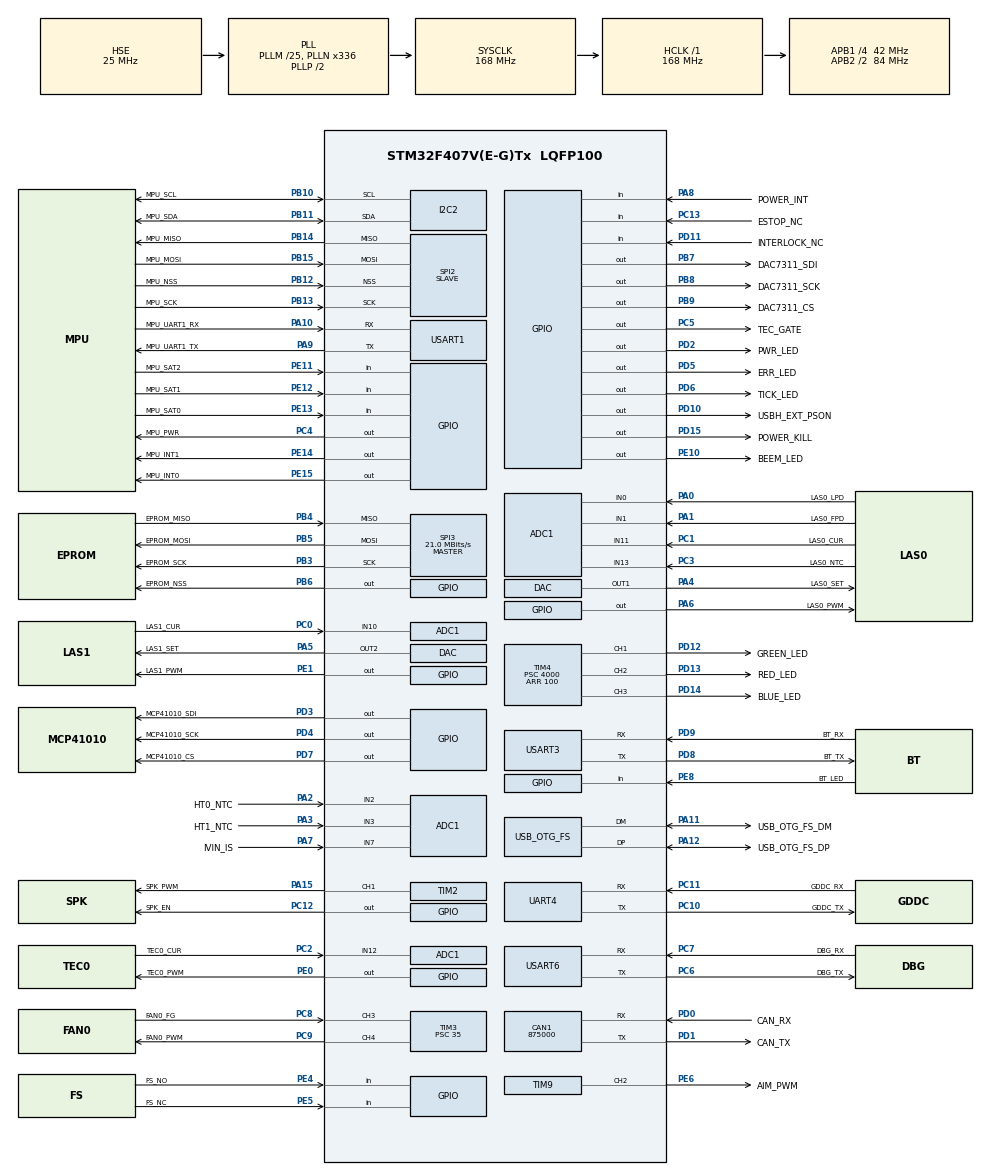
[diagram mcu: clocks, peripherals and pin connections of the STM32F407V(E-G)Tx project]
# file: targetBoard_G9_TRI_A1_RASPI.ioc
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ADC1.Channel-0\#ChannelRegularConversion=ADC_CHANNEL_0
ADC1.Channel-1\#ChannelRegularConversion=ADC_CHANNEL_1
ADC1.Channel-10\#ChannelRegularConversion=ADC_CHANNEL_VREFINT
ADC1.Channel-11\#ChannelRegularConversion=ADC_CHANNEL_VBAT
ADC1.Channel-2\#ChannelRegularConversion=ADC_CHANNEL_2
ADC1.Channel-3\#ChannelRegularConversion=ADC_CHANNEL_3
ADC1.Channel-4\#ChannelRegularConversion=ADC_CHANNEL_7
ADC1.Channel-5\#ChannelRegularConversion=ADC_CHANNEL_10
ADC1.Channel-6\#ChannelRegularConversion=ADC_CHANNEL_11
ADC1.Channel-7\#ChannelRegularConversion=ADC_CHANNEL_12
ADC1.Channel-8\#ChannelRegularConversion=ADC_CHANNEL_13
ADC1.Channel-9\#ChannelRegularConversion=ADC_CHANNEL_TEMPSENSOR
ADC1.ContinuousConvMode=ENABLE
ADC1.DMAContinuousRequests=ENABLE
ADC1.NbrOfConversion=12
ADC1.NbrOfConversionFlag=1
ADC1.Rank-0\#ChannelRegularConversion=1
ADC1.Rank-1\#ChannelRegularConversion=2
ADC1.Rank-10\#ChannelRegularConversion=11
ADC1.Rank-11\#ChannelRegularConversion=12
ADC1.Rank-2\#ChannelRegularConversion=3
ADC1.Rank-3\#ChannelRegularConversion=4
ADC1.Rank-4\#ChannelRegularConversion=5
ADC1.Rank-5\#ChannelRegularConversion=6
ADC1.Rank-6\#ChannelRegularConversion=7
ADC1.Rank-7\#ChannelRegularConversion=8
ADC1.Rank-8\#ChannelRegularConversion=9
ADC1.Rank-9\#ChannelRegularConversion=10
ADC1.SamplingTime-0\#ChannelRegularConversion=ADC_SAMPLETIME_144CYCLES
ADC1.SamplingTime-1\#ChannelRegularConversion=ADC_SAMPLETIME_144CYCLES
ADC1.SamplingTime-10\#ChannelRegularConversion=ADC_SAMPLETIME_144CYCLES
ADC1.SamplingTime-11\#ChannelRegularConversion=ADC_SAMPLETIME_144CYCLES
ADC1.SamplingTime-2\#ChannelRegularConversion=ADC_SAMPLETIME_144CYCLES
ADC1.SamplingTime-3\#ChannelRegularConversion=ADC_SAMPLETIME_144CYCLES
ADC1.SamplingTime-4\#ChannelRegularConversion=ADC_SAMPLETIME_144CYCLES
ADC1.SamplingTime-5\#ChannelRegularConversion=ADC_SAMPLETIME_144CYCLES
ADC1.SamplingTime-6\#ChannelRegularConversion=ADC_SAMPLETIME_144CYCLES
ADC1.SamplingTime-7\#ChannelRegularConversion=ADC_SAMPLETIME_144CYCLES
ADC1.SamplingTime-8\#ChannelRegularConversion=ADC_SAMPLETIME_144CYCLES
ADC1.SamplingTime-9\#ChannelRegularConversion=ADC_SAMPLETIME_144CYCLES
ADC1.ScanConvMode=ENABLE
ADC1.master=1
CAN1.BS1=CAN_BS1_1TQ
CAN1.BS2=CAN_BS2_1TQ
CAN1.CalculateBaudRate=875000
CAN1.CalculateTimeBit=1142
CAN1.CalculateTimeQuantum=380.95238095238096
DAC.DAC_Trigger=DAC_TRIGGER_NONE
Dma.ADC1.0.Direction=DMA_PERIPH_TO_MEMORY
Dma.ADC1.0.FIFOMode=DMA_FIFOMODE_DISABLE
Dma.ADC1.0.Instance=DMA2_Stream0
Dma.ADC1.0.MemDataAlignment=DMA_MDATAALIGN_HALFWORD
Dma.ADC1.0.MemInc=DMA_MINC_ENABLE
Dma.ADC1.0.Mode=DMA_NORMAL
Dma.ADC1.0.PeriphDataAlignment=DMA_PDATAALIGN_HALFWORD
Dma.ADC1.0.PeriphInc=DMA_PINC_DISABLE
Dma.ADC1.0.Priority=DMA_PRIORITY_LOW
Dma.Request0=ADC1
FATFS._CODE_PAGE=437
FATFS._FS_EXFAT=1
FATFS._FS_LOCK=255
FATFS._STRF_ENCODE=0
FATFS._USE_CHMOD=1
FATFS._USE_EXPAND=1
FATFS._USE_FIND=1
FATFS._USE_FORWARD=1
FATFS._USE_LABEL=1
FATFS._USE_LFN=3
FATFS._USE_MUTEX=1
FREERTOS.Tasks01=defaultTask,24,512,StartDefaultTask,Default,NULL,Dynamic,NULL,NULL;mainAppTask,24,10240,StartMainAppTask,As external,NULL,Dynamic,NULL,NULL
FREERTOS.configENABLE_FPU=1
FREERTOS.configMINIMAL_STACK_SIZE=512
FREERTOS.configTOTAL_HEAP_SIZE=49152
FREERTOS.configUSE_APPLICATION_TASK_TAG=1
I2C2.I2C_Mode=I2C_Fast
Mcu.Family=STM32F4
Mcu.Name=STM32F407V(E-G)Tx
Mcu.Package=LQFP100
NVIC.DMA2_Stream0_IRQn=true\:5\:0\:false\:false\:true\:true\:false\:true\:true
NVIC.OTG_FS_IRQn=true\:5\:0\:false\:false\:true\:true\:false\:true\:true
NVIC.PriorityGroup=NVIC_PRIORITYGROUP_4
NVIC.TIM7_IRQn=true\:5\:0\:false\:false\:true\:true\:true\:true\:true
NVIC.TIM8_TRG_COM_TIM14_IRQn=true\:5\:0\:false\:false\:true\:true\:true\:true\:true
NVIC.TIM8_UP_TIM13_IRQn=true\:15\:0\:false\:false\:true\:false\:false\:true\:true
NVIC.TimeBase=TIM8_UP_TIM13_IRQn
NVIC.TimeBaseIP=TIM13
NVIC.UART4_IRQn=true\:5\:0\:false\:false\:true\:true\:true\:true\:true
PA0-WKUP.GPIO_Label=LAS0_LPD
PA0-WKUP.Signal=ADCx_IN0
PA1.GPIO_Label=LAS0_FPD
PA1.Signal=ADCx_IN1
PA10.GPIO_Label=MPU_UART1_RX
PA10.GPIO_PuPd=GPIO_PULLDOWN
PA10.GPIO_Speed=GPIO_SPEED_FREQ_MEDIUM
PA10.Mode=Asynchronous
PA10.Signal=USART1_RX
PA11.GPIO_Label=USB_OTG_FS_DM
PA11.Mode=Host_Only
PA11.Signal=USB_OTG_FS_DM
PA12.GPIO_Label=USB_OTG_FS_DP
PA12.Mode=Host_Only
PA12.Signal=USB_OTG_FS_DP
PA13.Mode=Serial_Wire
PA13.Signal=SYS_JTMS-SWDIO
PA14.Mode=Serial_Wire
PA14.Signal=SYS_JTCK-SWCLK
PA15.GPIO_Label=SPK_PWM
PA15.GPIO_PuPd=GPIO_PULLDOWN
PA15.Signal=S_TIM2_CH1_ETR
PA2.GPIO_Label=HT0_NTC
PA2.Signal=ADCx_IN2
PA3.GPIO_Label=HT1_NTC
PA3.Signal=ADCx_IN3
PA4.GPIO_Label=LAS0_SET
PA4.Signal=COMP_DAC1_group
PA5.GPIO_Label=LAS1_SET
PA5.Signal=COMP_DAC2_group
PA6.GPIO_Label=LAS0_PWM
PA6.GPIO_PuPd=GPIO_PULLDOWN
PA6.Signal=GPIO_Output
PA7.GPIO_Label=IVIN_IS
PA7.Signal=ADCx_IN7
PA8.GPIO_Label=POWER_INT
PA8.Signal=GPIO_Input
PA9.GPIO_Label=MPU_UART1_TX
PA9.GPIO_PuPd=GPIO_PULLDOWN
PA9.GPIO_Speed=GPIO_SPEED_FREQ_MEDIUM
PA9.Mode=Asynchronous
PA9.Signal=USART1_TX
PB10.GPIO_Label=MPU_SCL
PB10.Mode=I2C
PB10.Signal=I2C2_SCL
PB11.GPIO_Label=MPU_SDA
PB11.Mode=I2C
PB11.Signal=I2C2_SDA
PB12.GPIO_Label=MPU_NSS
PB12.GPIO_PuPd=GPIO_PULLUP
PB12.Mode=NSS_Signal_Hard_Input
PB12.Signal=SPI2_NSS
PB13.GPIO_Label=MPU_SCK
PB13.GPIO_PuPd=GPIO_NOPULL
PB13.Mode=Full_Duplex_Slave
PB13.Signal=SPI2_SCK
PB14.GPIO_Label=MPU_MISO
PB14.GPIO_PuPd=GPIO_NOPULL
PB14.Mode=Full_Duplex_Slave
PB14.Signal=SPI2_MISO
PB15.GPIO_Label=MPU_MOSI
PB15.GPIO_PuPd=GPIO_NOPULL
PB15.Mode=Full_Duplex_Slave
PB15.Signal=SPI2_MOSI
PB3.GPIO_Label=EPROM_SCK
PB3.GPIO_PuPd=GPIO_NOPULL
PB3.Mode=Full_Duplex_Master
PB3.Signal=SPI3_SCK
PB4.GPIO_Label=EPROM_MISO
PB4.GPIO_PuPd=GPIO_NOPULL
PB4.Mode=Full_Duplex_Master
PB4.Signal=SPI3_MISO
PB5.GPIO_Label=EPROM_MOSI
PB5.GPIO_PuPd=GPIO_NOPULL
PB5.Mode=Full_Duplex_Master
PB5.Signal=SPI3_MOSI
PB6.GPIO_Label=EPROM_NSS
PB6.GPIO_PuPd=GPIO_PULLUP
PB6.GPIO_Speed=GPIO_SPEED_FREQ_VERY_HIGH
PB6.PinState=GPIO_PIN_SET
PB6.Signal=GPIO_Output
PB7.GPIO_Label=DAC7311_SDI
PB7.GPIO_PuPd=GPIO_PULLDOWN
PB7.GPIO_Speed=GPIO_SPEED_FREQ_VERY_HIGH
PB7.Signal=GPIO_Output
PB8.GPIO_Label=DAC7311_SCK
PB8.GPIO_PuPd=GPIO_PULLDOWN
PB8.GPIO_Speed=GPIO_SPEED_FREQ_VERY_HIGH
PB8.Signal=GPIO_Output
PB9.GPIO_Label=DAC7311_CS
PB9.GPIO_PuPd=GPIO_PULLUP
PB9.GPIO_Speed=GPIO_SPEED_FREQ_VERY_HIGH
PB9.Signal=GPIO_Output
PC0.GPIO_Label=LAS1_CUR
PC0.Signal=ADCx_IN10
PC1.GPIO_Label=LAS0_CUR
PC1.Signal=ADCx_IN11
PC10.GPIO_Label=GDDC_TX
PC10.GPIO_PuPd=GPIO_PULLDOWN
PC10.GPIO_Speed=GPIO_SPEED_FREQ_MEDIUM
PC10.Mode=Asynchronous
PC10.Signal=UART4_TX
PC11.GPIO_Label=GDDC_RX
PC11.GPIO_PuPd=GPIO_PULLDOWN
PC11.GPIO_Speed=GPIO_SPEED_FREQ_MEDIUM
PC11.Mode=Asynchronous
PC11.Signal=UART4_RX
PC12.GPIO_Label=SPK_EN
PC12.GPIO_PuPd=GPIO_PULLUP
PC12.Signal=GPIO_Output
PC13-ANTI_TAMP.GPIO_Label=ESTOP_NC
PC13-ANTI_TAMP.GPIO_PuPd=GPIO_PULLUP
PC13-ANTI_TAMP.Signal=GPIO_Input
PC2.GPIO_Label=TEC0_CUR
PC2.Signal=ADCx_IN12
PC3.GPIO_Label=LAS0_NTC
PC3.Signal=ADCx_IN13
PC4.GPIO_Label=MPU_PWR
PC4.GPIO_PuPd=GPIO_PULLUP
PC4.Signal=GPIO_Output
PC5.GPIO_Label=TEC_GATE
PC5.GPIO_PuPd=GPIO_PULLDOWN
PC5.Signal=GPIO_Output
PC6.GPIO_Label=DBG_TX
PC6.GPIO_PuPd=GPIO_PULLDOWN
PC6.GPIO_Speed=GPIO_SPEED_FREQ_MEDIUM
PC6.Mode=Asynchronous
PC6.Signal=USART6_TX
PC7.GPIO_Label=DBG_RX
PC7.GPIO_PuPd=GPIO_PULLDOWN
PC7.GPIO_Speed=GPIO_SPEED_FREQ_MEDIUM
PC7.Mode=Asynchronous
PC7.Signal=USART6_RX
PC8.GPIO_Label=FAN0_FG
PC8.GPIO_PuPd=GPIO_PULLUP
PC8.Signal=S_TIM3_CH3
PC9.GPIO_Label=FAN0_PWM
PC9.GPIO_PuPd=GPIO_PULLUP
PC9.Signal=S_TIM3_CH4
PD0.GPIO_Label=CAN_RX
PD0.Mode=CAN_Activate
PD0.Signal=CAN1_RX
PD1.GPIO_Label=CAN_TX
PD1.Mode=CAN_Activate
PD1.Signal=CAN1_TX
PD10.GPIO_Label=USBH_EXT_PSON
PD10.GPIO_PuPd=GPIO_PULLDOWN
PD10.Signal=GPIO_Output
PD11.GPIO_Label=INTERLOCK_NC
PD11.GPIO_PuPd=GPIO_PULLUP
PD11.Signal=GPIO_Input
PD12.GPIO_Label=GREEN_LED
PD12.GPIO_PuPd=GPIO_PULLDOWN
PD12.Signal=S_TIM4_CH1
PD13.GPIO_Label=RED_LED
PD13.GPIO_PuPd=GPIO_PULLDOWN
PD13.Signal=S_TIM4_CH2
PD14.GPIO_Label=BLUE_LED
PD14.GPIO_PuPd=GPIO_PULLDOWN
PD14.Signal=S_TIM4_CH3
PD15.GPIO_Label=POWER_KILL
PD15.GPIO_PuPd=GPIO_PULLDOWN
PD15.Signal=GPIO_Output
PD2.GPIO_Label=PWR_LED
PD2.GPIO_PuPd=GPIO_PULLUP
PD2.Signal=GPIO_Output
PD3.GPIO_Label=MCP41010_SDI
PD3.GPIO_PuPd=GPIO_PULLDOWN
PD3.GPIO_Speed=GPIO_SPEED_FREQ_VERY_HIGH
PD3.Signal=GPIO_Output
PD4.GPIO_Label=MCP41010_SCK
PD4.GPIO_PuPd=GPIO_PULLDOWN
PD4.GPIO_Speed=GPIO_SPEED_FREQ_VERY_HIGH
PD4.Signal=GPIO_Output
PD5.GPIO_Label=ERR_LED
PD5.GPIO_PuPd=GPIO_PULLDOWN
PD5.Signal=GPIO_Output
PD6.GPIO_Label=TICK_LED
PD6.GPIO_PuPd=GPIO_PULLDOWN
PD6.Signal=GPIO_Output
PD7.GPIO_Label=MCP41010_CS
PD7.GPIO_PuPd=GPIO_PULLUP
PD7.GPIO_Speed=GPIO_SPEED_FREQ_VERY_HIGH
PD7.Signal=GPIO_Output
PD8.GPIO_Label=BT_TX
PD8.GPIO_PuPd=GPIO_PULLDOWN
PD8.GPIO_Speed=GPIO_SPEED_FREQ_MEDIUM
PD8.Mode=Asynchronous
PD8.Signal=USART3_TX
PD9.GPIO_Label=BT_RX
PD9.GPIO_PuPd=GPIO_PULLDOWN
PD9.GPIO_Speed=GPIO_SPEED_FREQ_MEDIUM
PD9.Mode=Asynchronous
PD9.Signal=USART3_RX
PE0.GPIO_Label=TEC0_PWM
PE0.GPIO_PuPd=GPIO_PULLDOWN
PE0.Signal=GPIO_Output
PE1.GPIO_Label=LAS1_PWM
PE1.GPIO_PuPd=GPIO_PULLDOWN
PE1.Signal=GPIO_Output
PE10.GPIO_Label=BEEM_LED
PE10.GPIO_PuPd=GPIO_PULLDOWN
PE10.Signal=GPIO_Output
PE11.GPIO_Label=MPU_SAT2
PE11.GPIO_PuPd=GPIO_PULLDOWN
PE11.Signal=GPIO_Input
PE12.GPIO_Label=MPU_SAT1
PE12.GPIO_PuPd=GPIO_PULLDOWN
PE12.Signal=GPIO_Input
PE13.GPIO_Label=MPU_SAT0
PE13.GPIO_PuPd=GPIO_PULLDOWN
PE13.Signal=GPIO_Input
PE14.GPIO_Label=MPU_INT1
PE14.GPIO_PuPd=GPIO_PULLUP
PE14.Signal=GPIO_Output
PE15.GPIO_Label=MPU_INT0
PE15.GPIO_PuPd=GPIO_PULLUP
PE15.Signal=GPIO_Output
PE4.GPIO_Label=FS_NO
PE4.Signal=GPIO_Input
PE5.GPIO_Label=FS_NC
PE5.Signal=GPIO_Input
PE6.GPIO_Label=AIM_PWM
PE6.GPIO_PuPd=GPIO_PULLDOWN
PE6.Signal=S_TIM9_CH2
PE8.GPIO_Label=BT_LED
PE8.GPIO_PuPd=GPIO_PULLUP
PE8.Signal=GPIO_Input
PH0-OSC_IN.Mode=HSE-External-Oscillator
PH0-OSC_IN.Signal=RCC_OSC_IN
PH1-OSC_OUT.Mode=HSE-External-Oscillator
PH1-OSC_OUT.Signal=RCC_OSC_OUT
ProjectManager.HeapSize=0x2000
ProjectManager.StackSize=0x1000
ProjectManager.TargetToolchain=MDK-ARM V5.32
RCC.48MHZClocksFreq_Value=48000000
RCC.AHBFreq_Value=168000000
RCC.APB1CLKDivider=RCC_HCLK_DIV4
RCC.APB1Freq_Value=42000000
RCC.APB1TimFreq_Value=84000000
RCC.APB2CLKDivider=RCC_HCLK_DIV2
RCC.APB2Freq_Value=84000000
RCC.APB2TimFreq_Value=168000000
RCC.CortexFreq_Value=168000000
RCC.HCLKFreq_Value=168000000
RCC.HSE_Timout=400
RCC.HSE_VALUE=25000000
RCC.HSI_VALUE=16000000
RCC.LSE_VALUE=32768
RCC.PLLM=25
RCC.PLLN=336
RCC.PLLQ=7
RCC.PWR_Regulator_Voltage_Scale=PWR_REGULATOR_VOLTAGE_SCALE1
RCC.RCC_RTC_Clock_Source=RCC_RTCCLKSOURCE_LSI
RCC.RCC_RTC_Clock_SourceVirtual=RCC_RTCCLKSOURCE_LSE
RCC.RCC_RTC_Clock_Source_FROM_HSE=RCC_RTCCLKSOURCE_HSE_DIV25
RCC.SYSCLKFreq_VALUE=168000000
RCC.SYSCLKSource=RCC_SYSCLKSOURCE_PLLCLK
RCC.VCOOutputFreq_Value=336000000
SH.ADCx_IN0.0=ADC1_IN0,IN0
SH.ADCx_IN1.0=ADC1_IN1,IN1
SH.ADCx_IN10.0=ADC1_IN10,IN10
SH.ADCx_IN11.0=ADC1_IN11,IN11
SH.ADCx_IN12.0=ADC1_IN12,IN12
SH.ADCx_IN13.0=ADC1_IN13,IN13
SH.ADCx_IN2.0=ADC1_IN2,IN2
SH.ADCx_IN3.0=ADC1_IN3,IN3
SH.ADCx_IN7.0=ADC1_IN7,IN7
SH.COMP_DAC1_group.0=DAC_OUT1,DAC_OUT1
SH.COMP_DAC2_group.0=DAC_OUT2,DAC_OUT2
SH.S_TIM2_CH1_ETR.0=TIM2_CH1,PWM Generation1 CH1
SH.S_TIM3_CH3.0=TIM3_CH3,Input_Capture3_from_TI3
SH.S_TIM3_CH4.0=TIM3_CH4,PWM Generation4 CH4
SH.S_TIM4_CH1.0=TIM4_CH1,PWM Generation1 CH1
SH.S_TIM4_CH2.0=TIM4_CH2,PWM Generation2 CH2
SH.S_TIM4_CH3.0=TIM4_CH3,PWM Generation3 CH3
SH.S_TIM9_CH2.0=TIM9_CH2,PWM Generation2 CH2
SPI2.Direction=SPI_DIRECTION_2LINES
SPI2.Mode=SPI_MODE_SLAVE
SPI2.VirtualNSS=VM_NSSHARD
SPI2.VirtualType=VM_SLAVE
SPI3.BaudRatePrescaler=SPI_BAUDRATEPRESCALER_2
SPI3.CLKPhase=SPI_PHASE_1EDGE
SPI3.CLKPolarity=SPI_POLARITY_LOW
SPI3.CalculateBaudRate=21.0 MBits/s
SPI3.Direction=SPI_DIRECTION_2LINES
SPI3.Mode=SPI_MODE_MASTER
SPI3.VirtualType=VM_MASTER
TIM14.Period=1000
TIM14.Prescaler=84
TIM2.AutoReloadPreload=TIM_AUTORELOAD_PRELOAD_ENABLE
TIM2.Channel-PWM\ Generation1\ CH1=TIM_CHANNEL_1
TIM2.Period=1000
TIM2.Prescaler=500
TIM3.AutoReloadPreload=TIM_AUTORELOAD_PRELOAD_ENABLE
TIM3.Channel-Input_Capture3_from_TI3=TIM_CHANNEL_3
TIM3.Channel-PWM\ Generation4\ CH4=TIM_CHANNEL_4
TIM3.Period=100
TIM3.Prescaler=35
TIM4.AutoReloadPreload=TIM_AUTORELOAD_PRELOAD_ENABLE
TIM4.Channel-PWM\ Generation1\ CH1=TIM_CHANNEL_1
TIM4.Channel-PWM\ Generation2\ CH2=TIM_CHANNEL_2
TIM4.Channel-PWM\ Generation3\ CH3=TIM_CHANNEL_3
TIM4.Period=100
TIM4.Prescaler=4000
TIM7.AutoReloadPreload=TIM_AUTORELOAD_PRELOAD_ENABLE
TIM7.Period=1000
TIM7.Prescaler=84
TIM9.AutoReloadPreload=TIM_AUTORELOAD_PRELOAD_ENABLE
TIM9.Channel-PWM\ Generation2\ CH2=TIM_CHANNEL_2
TIM9.Period=5000
TIM9.Prescaler=96
UART4.VirtualMode=Asynchronous
USART1.VirtualMode=VM_ASYNC
USART3.VirtualMode=VM_ASYNC
USART6.VirtualMode=VM_ASYNC
USB_HOST.BSP.number=1
USB_HOST.USBH_DEBUG_LEVEL-ALL_Classes_FS=3
USB_HOST.USBH_HandleTypeDef-ALL_Classes_FS=hUsbHostFS
USB_HOST.VirtualModeFS=All_Classes
USB_HOST0.BSP.STBoard=false
USB_HOST0.BSP.api=Unknown
USB_HOST0.BSP.condition=ALL_SW_VBUS_DRIVE_FS \= false
USB_HOST0.BSP.instance=PD10
USB_HOST0.BSP.ip=GPIO
USB_HOST0.BSP.mode=Output
USB_HOST0.BSP.name=Drive_VBUS_FS
USB_HOST0.BSP.solution=PD10
USB_OTG_FS.VirtualMode=Host_Only
USB_OTG_FS.phy_itface=HCD_PHY_EMBEDDED
VP_ADC1_TempSens_Input.Mode=IN-TempSens
VP_ADC1_Vbat_Input.Mode=IN-Vbat
VP_ADC1_Vref_Input.Mode=IN-Vrefint
VP_CRC_VS_CRC.Mode=CRC_Activate
VP_FATFS_VS_USB.Mode=USB
VP_FREERTOS_VS_CMSIS_V2.Mode=CMSIS_V2
VP_RNG_VS_RNG.Mode=RNG_Activate
VP_SYS_VS_tim13.Mode=TIM13
VP_TIM14_VS_ClockSourceINT.Mode=Enable_Timer
VP_TIM2_VS_ClockSourceINT.Mode=Internal
VP_TIM3_VS_ClockSourceINT.Mode=Internal
VP_TIM4_VS_ClockSourceINT.Mode=Internal
VP_TIM7_VS_ClockSourceINT.Mode=Enable_Timer
VP_TIM9_VS_ClockSourceINT.Mode=Internal
VP_USB_HOST_VS_USB_HOST_ALL_CLASS_FS.Mode=ALL_Classes_FS
board=custom

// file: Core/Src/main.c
/* USER CODE BEGIN Header */
/**
  ******************************************************************************
  * @file           : main.c
  * @brief          : Main program body
  ******************************************************************************
  * @attention
  *
  * Copyright (c) 2026 STMicroelectronics.
  * All rights reserved.
  *
  * This software is licensed under terms that can be found in the LICENSE file
  * in the root directory of this software component.
  * If no LICENSE file comes with this software, it is provided AS-IS.
  *
  ******************************************************************************
  */
/* USER CODE END Header */
#include "main.h"
#include "cmsis_os.h"
#include "adc.h"
#include "can.h"
#include "crc.h"
#include "dac.h"
#include "dma.h"
#include "fatfs.h"
#include "i2c.h"
#include "rng.h"
#include "spi.h"
#include "tim.h"
#include "usart.h"
#include "usb_host.h"
#include "gpio.h"

/* USER CODE BEGIN Includes */
#include "sPlc.h"
/* USER CODE END Includes */

void SystemClock_Config(void);
void MX_FREERTOS_Init(void);

/* USER CODE BEGIN 0 */
extern void RtcCheckAndInit(void);
/* USER CODE END 0 */

int main(void)
{

  /* USER CODE BEGIN 1 */
	resetInit();//
  /* USER CODE END 1 */

  /* MCU Configuration--------------------------------------------------------*/

  /* Reset of all peripherals, Initializes the Flash interface and the Systick. */
  HAL_Init();

  /* Configure the system clock */
  SystemClock_Config();

  /* Initialize all configured peripherals */
  MX_GPIO_Init();
  MX_DMA_Init();
  MX_DAC_Init();
  MX_ADC1_Init();
  MX_SPI3_Init();
  MX_SPI2_Init();
  MX_USART1_UART_Init();
  MX_USART6_UART_Init();
  MX_CAN1_Init();
  MX_TIM4_Init();
  MX_USART3_UART_Init();
  MX_I2C2_Init();
  MX_TIM2_Init();
  MX_TIM3_Init();
  MX_TIM9_Init();
  MX_UART4_Init();
  MX_CRC_Init();
  MX_RNG_Init();
  MX_FATFS_Init();
  MX_TIM7_Init();
  MX_TIM14_Init();
  /* USER CODE BEGIN 2 */
  //tickCheckTask();
  /* USER CODE END 2 */

  /* Init scheduler */
  osKernelInitialize();  /* Call init function for freertos objects (in cmsis_os2.c) */
  MX_FREERTOS_Init();

  /* Start scheduler */
  osKernelStart();

  /* We should never get here as control is now taken by the scheduler */

  /* Infinite loop */
  while (1)
  {

  }
}

void SystemClock_Config(void)
{
  RCC_OscInitTypeDef RCC_OscInitStruct = {0};
  RCC_ClkInitTypeDef RCC_ClkInitStruct = {0};

  /** Configure the main internal regulator output voltage
  */
  __HAL_RCC_PWR_CLK_ENABLE();
  __HAL_PWR_VOLTAGESCALING_CONFIG(PWR_REGULATOR_VOLTAGE_SCALE1);

  /** Initializes the RCC Oscillators according to the specified parameters
  * in the RCC_OscInitTypeDef structure.
  */
  RCC_OscInitStruct.OscillatorType = RCC_OSCILLATORTYPE_HSE;
  RCC_OscInitStruct.HSEState = RCC_HSE_ON;
  RCC_OscInitStruct.PLL.PLLState = RCC_PLL_ON;
  RCC_OscInitStruct.PLL.PLLSource = RCC_PLLSOURCE_HSE;
  RCC_OscInitStruct.PLL.PLLM = 25;
  RCC_OscInitStruct.PLL.PLLN = 336;
  RCC_OscInitStruct.PLL.PLLP = RCC_PLLP_DIV2;
  RCC_OscInitStruct.PLL.PLLQ = 7;
  if (HAL_RCC_OscConfig(&RCC_OscInitStruct) != HAL_OK)
  {
    Error_Handler();
  }

  /** Initializes the CPU, AHB and APB buses clocks
  */
  RCC_ClkInitStruct.ClockType = RCC_CLOCKTYPE_HCLK|RCC_CLOCKTYPE_SYSCLK
                              |RCC_CLOCKTYPE_PCLK1|RCC_CLOCKTYPE_PCLK2;
  RCC_ClkInitStruct.SYSCLKSource = RCC_SYSCLKSOURCE_PLLCLK;
  RCC_ClkInitStruct.AHBCLKDivider = RCC_SYSCLK_DIV1;
  RCC_ClkInitStruct.APB1CLKDivider = RCC_HCLK_DIV4;
  RCC_ClkInitStruct.APB2CLKDivider = RCC_HCLK_DIV2;

  if (HAL_RCC_ClockConfig(&RCC_ClkInitStruct, FLASH_LATENCY_5) != HAL_OK)
  {
    Error_Handler();
  }
}

void HAL_TIM_PeriodElapsedCallback(TIM_HandleTypeDef *htim)
{
  if (htim->Instance == TIM13)
  {
    HAL_IncTick();
  }
  /* USER CODE BEGIN Callback 1 */
	if(htim->Instance == CONFIG_SPLC_TIM) {
		sPlcTimerIsr();
	}
	if(htim->Instance == CONFIG_LASER_TIM){
		sPlcLaserTimerIsr();
	}
  /* USER CODE END Callback 1 */
}

void Error_Handler(void)
{
  __disable_irq();
  while (1)
  {
  }
}

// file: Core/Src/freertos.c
/* USER CODE BEGIN Header */
/**
  ******************************************************************************
  * File Name          : freertos.c
  * Description        : Code for freertos applications
  ******************************************************************************
  * @attention
  *
  * Copyright (c) 2026 STMicroelectronics.
  * All rights reserved.
  *
  * This software is licensed under terms that can be found in the LICENSE file
  * in the root directory of this software component.
  * If no LICENSE file comes with this software, it is provided AS-IS.
  *
  ******************************************************************************
  */
/* USER CODE END Header */

#include "FreeRTOS.h"
#include "task.h"
#include "main.h"
#include "cmsis_os.h"

/* Definitions for defaultTask */
osThreadId_t defaultTaskHandle;
const osThreadAttr_t defaultTask_attributes = {
  .name = "defaultTask",
  .stack_size = 512 * 4,
  .priority = (osPriority_t) osPriorityNormal,
};
/* Definitions for mainAppTask */
osThreadId_t mainAppTaskHandle;
const osThreadAttr_t mainAppTask_attributes = {
  .name = "mainAppTask",
  .stack_size = 10240 * 4,
  .priority = (osPriority_t) osPriorityNormal,
};

void StartDefaultTask(void *argument);
extern void StartMainAppTask(void *argument);

extern void MX_USB_HOST_Init(void);
void MX_FREERTOS_Init(void); /* (MISRA C 2004 rule 8.1) */

void MX_FREERTOS_Init(void) {

  /* Create the thread(s) */
  /* creation of defaultTask */
  defaultTaskHandle = osThreadNew(StartDefaultTask, NULL, &defaultTask_attributes);

  /* creation of mainAppTask */
  mainAppTaskHandle = osThreadNew(StartMainAppTask, NULL, &mainAppTask_attributes);

}

void StartDefaultTask(void *argument)
{
  /* init code for USB_HOST */
  MX_USB_HOST_Init();
  for(;;)
  {
    osDelay(1);
  }
}
